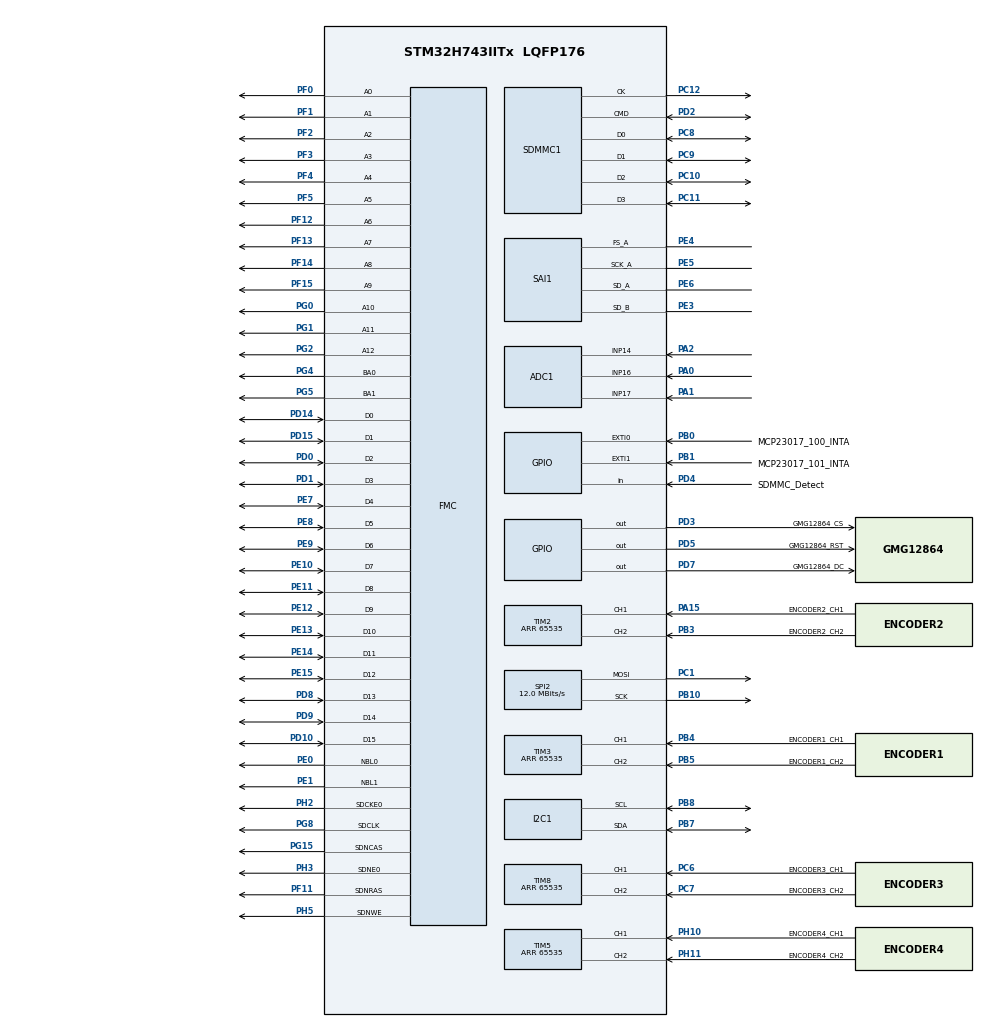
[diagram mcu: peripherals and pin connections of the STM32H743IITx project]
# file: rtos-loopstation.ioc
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ADC1.Channel-2\#ChannelRegularConversion=ADC_CHANNEL_16
ADC1.Channel-3\#ChannelRegularConversion=ADC_CHANNEL_17
ADC1.Channel-4\#ChannelRegularConversion=ADC_CHANNEL_14
ADC1.ContinuousConvMode=DISABLE
ADC1.EOCSelection=ADC_EOC_SINGLE_CONV
ADC1.LowPowerAutoWait=ENABLE
ADC1.NbrOfConversion=3
ADC1.NbrOfConversionFlag=1
ADC1.OffsetNumber-2\#ChannelRegularConversion=ADC_OFFSET_NONE
ADC1.OffsetNumber-3\#ChannelRegularConversion=ADC_OFFSET_NONE
ADC1.OffsetNumber-4\#ChannelRegularConversion=ADC_OFFSET_NONE
ADC1.OffsetSignedSaturation-2\#ChannelRegularConversion=DISABLE
ADC1.OffsetSignedSaturation-3\#ChannelRegularConversion=DISABLE
ADC1.OffsetSignedSaturation-4\#ChannelRegularConversion=DISABLE
ADC1.Overrun=ADC_OVR_DATA_PRESERVED
ADC1.Rank-2\#ChannelRegularConversion=1
ADC1.Rank-3\#ChannelRegularConversion=2
ADC1.Rank-4\#ChannelRegularConversion=3
ADC1.SamplingTime-2\#ChannelRegularConversion=ADC_SAMPLETIME_64CYCLES_5
ADC1.SamplingTime-3\#ChannelRegularConversion=ADC_SAMPLETIME_64CYCLES_5
ADC1.SamplingTime-4\#ChannelRegularConversion=ADC_SAMPLETIME_64CYCLES_5
ADC1.master=1
CORTEX_M7.AccessPermission_S-Cortex_Memory_Protection_Unit_Region1_Settings_S=MPU_REGION_FULL_ACCESS
CORTEX_M7.BaseAddress_S-Cortex_Memory_Protection_Unit_Region1_Settings_S=0xC0000000
CORTEX_M7.Enable_S-Cortex_Memory_Protection_Unit_Region1_Settings_S=MPU_REGION_ENABLE
CORTEX_M7.IsBufferable_S-Cortex_Memory_Protection_Unit_Region1_Settings_S=MPU_ACCESS_BUFFERABLE
CORTEX_M7.IsCacheable_S-Cortex_Memory_Protection_Unit_Region1_Settings_S=MPU_ACCESS_CACHEABLE
CORTEX_M7.IsShareable_S-Cortex_Memory_Protection_Unit_Region1_Settings_S=MPU_ACCESS_SHAREABLE
CORTEX_M7.Size_S-Cortex_Memory_Protection_Unit_Region1_Settings_S=MPU_REGION_SIZE_32MB
CORTEX_M7.default_mode_Activation=1
Dma.Request0=SPI2_TX
Dma.Request1=SAI1_A
Dma.Request2=SAI1_B
Dma.SAI1_A.1.Direction=DMA_MEMORY_TO_PERIPH
Dma.SAI1_A.1.EventEnable=DISABLE
Dma.SAI1_A.1.FIFOMode=DMA_FIFOMODE_DISABLE
Dma.SAI1_A.1.Instance=DMA1_Stream1
Dma.SAI1_A.1.MemDataAlignment=DMA_MDATAALIGN_WORD
Dma.SAI1_A.1.MemInc=DMA_MINC_ENABLE
Dma.SAI1_A.1.Mode=DMA_CIRCULAR
Dma.SAI1_A.1.PeriphDataAlignment=DMA_PDATAALIGN_WORD
Dma.SAI1_A.1.PeriphInc=DMA_PINC_DISABLE
Dma.SAI1_A.1.Polarity=HAL_DMAMUX_REQ_GEN_RISING
Dma.SAI1_A.1.Priority=DMA_PRIORITY_HIGH
Dma.SAI1_A.1.RequestNumber=1
Dma.SAI1_A.1.SignalID=NONE
Dma.SAI1_A.1.SyncEnable=DISABLE
Dma.SAI1_A.1.SyncPolarity=HAL_DMAMUX_SYNC_NO_EVENT
Dma.SAI1_A.1.SyncRequestNumber=1
Dma.SAI1_A.1.SyncSignalID=NONE
Dma.SAI1_B.2.Direction=DMA_PERIPH_TO_MEMORY
Dma.SAI1_B.2.EventEnable=DISABLE
Dma.SAI1_B.2.FIFOMode=DMA_FIFOMODE_DISABLE
Dma.SAI1_B.2.Instance=DMA1_Stream2
Dma.SAI1_B.2.MemDataAlignment=DMA_MDATAALIGN_WORD
Dma.SAI1_B.2.MemInc=DMA_MINC_ENABLE
Dma.SAI1_B.2.Mode=DMA_CIRCULAR
Dma.SAI1_B.2.PeriphDataAlignment=DMA_PDATAALIGN_WORD
Dma.SAI1_B.2.PeriphInc=DMA_PINC_DISABLE
Dma.SAI1_B.2.Polarity=HAL_DMAMUX_REQ_GEN_RISING
Dma.SAI1_B.2.Priority=DMA_PRIORITY_LOW
Dma.SAI1_B.2.RequestNumber=1
Dma.SAI1_B.2.SignalID=NONE
Dma.SAI1_B.2.SyncEnable=DISABLE
Dma.SAI1_B.2.SyncPolarity=HAL_DMAMUX_SYNC_NO_EVENT
Dma.SAI1_B.2.SyncRequestNumber=1
Dma.SAI1_B.2.SyncSignalID=NONE
Dma.SPI2_TX.0.Direction=DMA_MEMORY_TO_PERIPH
Dma.SPI2_TX.0.EventEnable=DISABLE
Dma.SPI2_TX.0.FIFOMode=DMA_FIFOMODE_DISABLE
Dma.SPI2_TX.0.Instance=DMA1_Stream0
Dma.SPI2_TX.0.MemDataAlignment=DMA_MDATAALIGN_BYTE
Dma.SPI2_TX.0.MemInc=DMA_MINC_ENABLE
Dma.SPI2_TX.0.Mode=DMA_NORMAL
Dma.SPI2_TX.0.PeriphDataAlignment=DMA_PDATAALIGN_BYTE
Dma.SPI2_TX.0.PeriphInc=DMA_PINC_DISABLE
Dma.SPI2_TX.0.Polarity=HAL_DMAMUX_REQ_GEN_RISING
Dma.SPI2_TX.0.Priority=DMA_PRIORITY_LOW
Dma.SPI2_TX.0.RequestNumber=1
Dma.SPI2_TX.0.SignalID=NONE
Dma.SPI2_TX.0.SyncEnable=DISABLE
Dma.SPI2_TX.0.SyncPolarity=HAL_DMAMUX_SYNC_NO_EVENT
Dma.SPI2_TX.0.SyncRequestNumber=1
Dma.SPI2_TX.0.SyncSignalID=NONE
FATFS.BSP.number=1
FATFS0.BSP.STBoard=false
FATFS0.BSP.api=Unknown
FATFS0.BSP.instance=PD4
FATFS0.BSP.ip=GPIO
FATFS0.BSP.mode=Input
FATFS0.BSP.name=Detect_SDIO
FATFS0.BSP.solution=PD4
FMC.CASLatency1=FMC_SDRAM_CAS_LATENCY_2
FMC.ColumnBitsNumber1=FMC_SDRAM_COLUMN_BITS_NUM_9
FMC.ReadBurst1=FMC_SDRAM_RBURST_ENABLE
FMC.ReadBurst2=FMC_SDRAM_RBURST_ENABLE
FMC.ReadPipeDelay1=FMC_SDRAM_RPIPE_DELAY_0
FMC.SDClockPeriod1=FMC_SDRAM_CLOCK_PERIOD_3
FMC.SDClockPeriod2=FMC_SDRAM_CLOCK_PERIOD_3
FMC.WriteProtection1=FMC_SDRAM_WRITE_PROTECTION_DISABLE
FREERTOS.Events01=system_init_event,Dynamic,NULL
FREERTOS.Mutexes01=i2c1_mutex,Dynamic,NULL,Available;system_parameter_mutex,Dynamic,NULL,Available;fx_parameter_mutex,Dynamic,NULL,Available
FREERTOS.Queues01=input_event_queue,16,RtosMessage_InputEvent,0,Dynamic,NULL,NULL;display_snapshot_mailbox,1,RtosMessage_DisplaySnapshot,0,Dynamic,NULL,NULL;state_event_queue,16,RtosMessage_StateEvent,0,Dynamic,NULL,NULL;audio_event_snapshot_mailbox,1,RtosMessage_AudioEventSnapshot,0,Dynamic,NULL,NULL;audio_dma_event,16,RtosMessage_AudioDmaEvent,0,Dynamic,NULL,NULL
FREERTOS.Tasks01=defaultTask,8,128,StartDefaultTask,Default,NULL,Dynamic,NULL,NULL;inputTask,32,128,InputTask_Init,As external,&input_init_params,Dynamic,NULL,NULL;displayTask,16,512,DisplayTask_Init,As external,&display_init_params,Dynamic,NULL,NULL;stateTask,24,1024,StateTask_Init,As external,&state_init_params,Dynamic,NULL,NULL;adcInputTask,32,128,AdcInputTask_Init,As external,&adc_input_init_params,Dynamic,NULL,NULL;systemTask,55,1024,SystemTask_Init,As external,&system_init_params,Dynamic,NULL,NULL;audioTask,40,128,AudioTask_Init,As external,&audio_init_params,Dynamic,NULL,NULL
FREERTOS.configENABLE_FPU=1
FREERTOS.configRECORD_STACK_HIGH_ADDRESS=1
I2C1.Timing=0x307075B1
Mcu.Family=STM32H7
Mcu.Name=STM32H743IITx
Mcu.Package=LQFP176
Mdma.MDMA_Channel0.Request0=SW
Mdma.MDMA_Channel0.RequestsNb=1
Mdma.MDMA_Channel0.SW.0.BlockCount=0
Mdma.MDMA_Channel0.SW.0.BlockDataLength=0
Mdma.MDMA_Channel0.SW.0.BufferTransferLength=128
Mdma.MDMA_Channel0.SW.0.CircularMode=MDMA_LINEAR_LIST
Mdma.MDMA_Channel0.SW.0.DataAlignment=MDMA_DATAALIGN_PACKENABLE
Mdma.MDMA_Channel0.SW.0.DestBlockAddressOffset=0
Mdma.MDMA_Channel0.SW.0.DestBurst=MDMA_DEST_BURST_SINGLE
Mdma.MDMA_Channel0.SW.0.DestDataSize=MDMA_DEST_DATASIZE_WORD
Mdma.MDMA_Channel0.SW.0.DestinationInc=MDMA_DEST_INC_WORD
Mdma.MDMA_Channel0.SW.0.DstAddress=0
Mdma.MDMA_Channel0.SW.0.Endianness=MDMA_LITTLE_ENDIANNESS_PRESERVE
Mdma.MDMA_Channel0.SW.0.Instance=MDMA_Channel0
Mdma.MDMA_Channel0.SW.0.MaskAddress=0
Mdma.MDMA_Channel0.SW.0.MaskData=0
Mdma.MDMA_Channel0.SW.0.Priority=MDMA_PRIORITY_MEDIUM
Mdma.MDMA_Channel0.SW.0.Rank=First
Mdma.MDMA_Channel0.SW.0.SourceBlockAddressOffset=0
Mdma.MDMA_Channel0.SW.0.SourceBurst=MDMA_SOURCE_BURST_SINGLE
Mdma.MDMA_Channel0.SW.0.SourceDataSize=MDMA_SRC_DATASIZE_WORD
Mdma.MDMA_Channel0.SW.0.SourceInc=MDMA_SRC_INC_WORD
Mdma.MDMA_Channel0.SW.0.SrcAddress=0
Mdma.MDMA_Channel0.SW.0.TransferTriggerMode=MDMA_BLOCK_TRANSFER
Mdma.RequestSet0=MDMA_Channel0
Mdma.RequestSetsNb=1
NVIC.DMA1_Stream0_IRQn=true\:5\:0\:false\:false\:true\:true\:false\:true\:true
NVIC.DMA1_Stream1_IRQn=true\:5\:0\:false\:false\:true\:true\:false\:true\:true
NVIC.DMA1_Stream2_IRQn=true\:5\:0\:false\:false\:true\:true\:false\:true\:true
NVIC.EXTI0_IRQn=true\:5\:0\:false\:false\:true\:true\:true\:true\:true
NVIC.EXTI1_IRQn=true\:5\:0\:false\:false\:true\:true\:true\:true\:true
NVIC.MDMA_IRQn=true\:5\:0\:false\:false\:true\:false\:false\:true\:true
NVIC.PriorityGroup=NVIC_PRIORITYGROUP_4
NVIC.SPI2_IRQn=true\:5\:0\:false\:false\:true\:true\:false\:true\:true
NVIC.TIM2_IRQn=true\:5\:0\:false\:false\:true\:true\:true\:true\:true
NVIC.TIM3_IRQn=true\:5\:0\:false\:false\:true\:true\:true\:true\:true
NVIC.TIM5_IRQn=true\:5\:0\:false\:false\:true\:true\:true\:true\:true
NVIC.TIM7_IRQn=true\:15\:0\:false\:false\:true\:false\:false\:true\:true
NVIC.TIM8_CC_IRQn=true\:5\:0\:false\:false\:true\:true\:true\:true\:true
NVIC.TimeBase=TIM7_IRQn
NVIC.TimeBaseIP=TIM7
PA0.Mode=IN16-Single-Ended
PA0.Signal=ADC1_INP16
PA1.Mode=IN17-Single-Ended
PA1.Signal=ADC1_INP17
PA13\ (JTMS/SWDIO).Mode=Serial_Wire
PA13\ (JTMS/SWDIO).Signal=DEBUG_JTMS-SWDIO
PA14\ (JTCK/SWCLK).Mode=Serial_Wire
PA14\ (JTCK/SWCLK).Signal=DEBUG_JTCK-SWCLK
PA15\ (JTDI).GPIO_Label=ENCODER2_CH1
PA15\ (JTDI).GPIO_PuPd=GPIO_PULLUP
PA15\ (JTDI).Signal=S_TIM2_CH1_ETR
PA2.Signal=ADCx_INP14
PB0.GPIO_Label=MCP23017_100_INTA
PB0.Signal=GPXTI0
PB1.GPIO_Label=MCP23017_101_INTA
PB1.Signal=GPXTI1
PB10.Mode=TX_Only_Simplex_Unidirect_Master
PB10.Signal=SPI2_SCK
PB3\ (JTDO/TRACESWO).GPIO_Label=ENCODER2_CH2
PB3\ (JTDO/TRACESWO).GPIO_PuPd=GPIO_PULLUP
PB3\ (JTDO/TRACESWO).Signal=S_TIM2_CH2
PB4\ (NJTRST).GPIO_Label=ENCODER1_CH1
PB4\ (NJTRST).GPIO_PuPd=GPIO_PULLUP
PB4\ (NJTRST).Signal=S_TIM3_CH1
PB5.GPIO_Label=ENCODER1_CH2
PB5.GPIO_PuPd=GPIO_PULLUP
PB5.Signal=S_TIM3_CH2
PB7.Mode=I2C
PB7.Signal=I2C1_SDA
PB8.Mode=I2C
PB8.Signal=I2C1_SCL
PC1.Mode=TX_Only_Simplex_Unidirect_Master
PC1.Signal=SPI2_MOSI
PC10.Mode=SD_4_bits_Wide_bus
PC10.Signal=SDMMC1_D2
PC11.Mode=SD_4_bits_Wide_bus
PC11.Signal=SDMMC1_D3
PC12.GPIO_PuPd=GPIO_NOPULL
PC12.Mode=SD_4_bits_Wide_bus
PC12.Signal=SDMMC1_CK
PC6.GPIO_Label=ENCODER3_CH1
PC6.GPIO_PuPd=GPIO_PULLUP
PC6.Signal=S_TIM8_CH1
PC7.GPIO_Label=ENCODER3_CH2
PC7.GPIO_PuPd=GPIO_PULLUP
PC7.Signal=S_TIM8_CH2
PC8.GPIO_PuPd=GPIO_PULLUP
PC8.Mode=SD_4_bits_Wide_bus
PC8.Signal=SDMMC1_D0
PC9.Mode=SD_4_bits_Wide_bus
PC9.Signal=SDMMC1_D1
PD0.Signal=FMC_D2_DA2
PD1.Signal=FMC_D3_DA3
PD10.Signal=FMC_D15_DA15
PD14.Signal=FMC_D0_DA0
PD15.Signal=FMC_D1_DA1
PD2.GPIO_PuPd=GPIO_PULLUP
PD2.Mode=SD_4_bits_Wide_bus
PD2.Signal=SDMMC1_CMD
PD3.GPIO_Label=GMG12864_CS
PD3.Signal=GPIO_Output
PD4.GPIO_Label=SDMMC_Detect
PD4.GPIO_PuPd=GPIO_PULLUP
PD4.Signal=GPIO_Input
PD5.GPIO_Label=GMG12864_RST
PD5.Signal=GPIO_Output
PD7.GPIO_Label=GMG12864_DC
PD7.Signal=GPIO_Output
PD8.Signal=FMC_D13_DA13
PD9.Signal=FMC_D14_DA14
PE0.Signal=FMC_NBL0
PE1.Signal=FMC_NBL1
PE10.Signal=FMC_D7_DA7
PE11.Signal=FMC_D8_DA8
PE12.Signal=FMC_D9_DA9
PE13.Signal=FMC_D10_DA10
PE14.Signal=FMC_D11_DA11
PE15.Signal=FMC_D12_DA12
PE3.Mode=SAI_B_SyncSlave
PE3.PinAttribute=Free
PE3.Signal=SAI1_SD_B
PE4.Mode=SAI_A_Master
PE4.PinAttribute=Free
PE4.Signal=SAI1_FS_A
PE5.Mode=SAI_A_Master
PE5.PinAttribute=Free
PE5.Signal=SAI1_SCK_A
PE6.Mode=SAI_A_Master
PE6.PinAttribute=Free
PE6.Signal=SAI1_SD_A
PE7.Signal=FMC_D4_DA4
PE8.Signal=FMC_D5_DA5
PE9.Signal=FMC_D6_DA6
PF0.PinAttribute=Free
PF0.Signal=FMC_A0
PF1.Signal=FMC_A1
PF11.Signal=FMC_SDNRAS
PF12.Signal=FMC_A6
PF13.Signal=FMC_A7
PF14.Signal=FMC_A8
PF15.Signal=FMC_A9
PF2.Signal=FMC_A2
PF3.Signal=FMC_A3
PF4.Signal=FMC_A4
PF5.Signal=FMC_A5
PG0.Signal=FMC_A10
PG1.Signal=FMC_A11
PG15.Signal=FMC_SDNCAS
PG2.Signal=FMC_A12
PG4.Signal=FMC_A14_BA0
PG5.Signal=FMC_A15_BA1
PG8.Signal=FMC_SDCLK
PH10.GPIO_Label=ENCODER4_CH1
PH10.GPIO_PuPd=GPIO_PULLUP
PH10.Signal=S_TIM5_CH1
PH11.GPIO_Label=ENCODER4_CH2
PH11.GPIO_PuPd=GPIO_PULLUP
PH11.Signal=S_TIM5_CH2
PH2.Mode=SdramChipSelect1_1
PH2.Signal=FMC_SDCKE0
PH3.Mode=SdramChipSelect1_1
PH3.Signal=FMC_SDNE0
PH5.Signal=FMC_SDNWE
ProjectManager.HeapSize=0x200
ProjectManager.StackSize=0x400
ProjectManager.TargetToolchain=CMake
RCC.ADCFreq_Value=80000000
RCC.APB1Freq_Value=120000000
RCC.APB2Freq_Value=120000000
RCC.APB3Freq_Value=120000000
RCC.APB4Freq_Value=120000000
RCC.CortexFreq_Value=480000000
RCC.D1PPRE=RCC_APB3_DIV2
RCC.D2PPRE1=RCC_APB1_DIV2
RCC.D2PPRE2=RCC_APB2_DIV2
RCC.D3PPRE=RCC_APB4_DIV2
RCC.DIVM1=4
RCC.DIVM2=4
RCC.DIVM3=25
RCC.DIVN1=60
RCC.DIVN2=10
RCC.DIVN3=176
RCC.DIVP3=40
RCC.DIVQ1=5
RCC.DIVR1=42
RCC.HCLKFreq_Value=240000000
RCC.HPRE=RCC_HCLK_DIV2
RCC.PLL2FRACN=0
RCC.PLL3FRACN=3277
RCC.PLLFRACN=0
RCC.SAI1CLockSelection=RCC_SAI1CLKSOURCE_PLL3
RCC.SYSCLKFreq_VALUE=480000000
RCC.SYSCLKSource=RCC_SYSCLKSOURCE_PLLCLK
RCC.USBFreq_Value=192000000
SAI1.AudioFrequency-SAI_A_Master=SAI_AUDIO_FREQUENCY_44K
SAI1.BasicDataSize-SAI_A_Master=SAI_PROTOCOL_DATASIZE_32BIT
SAI1.BasicDataSize-SAI_B_SyncSlave=SAI_PROTOCOL_DATASIZE_32BIT
SAI1.ErrorAudioFreq-SAI_A_Master=0.0 %
SAI1.InitProtocol-SAI_A_Master=Enable
SAI1.InitProtocol-SAI_B_SyncSlave=Enable
SAI1.Instance-SAI_A_Master=SAI$Index_Block_A
SAI1.Instance-SAI_B_SyncSlave=SAI$Index_Block_B
SAI1.MClockEnable=SAI_MASTERCLOCK_DISABLE
SAI1.MClockEnable-SAI_A_Master=SAI_MASTERCLOCK_DISABLE
SAI1.RealAudioFreq-SAI_A_Master=44.1 KHz
SAI1.VirtualMode-SAI_A_Master=VM_MASTER
SAI1.VirtualMode-SAI_B_SyncSlave=VM_SLAVE
SAI1.VirtualProtocol-SAI_A_BASIC=VM_BASIC_PROTOCOL
SAI1.VirtualProtocol-SAI_B_BASIC=VM_BASIC_PROTOCOL
SDMMC1.ClockDiv=24
SH.ADCx_INP14.0=ADC1_INP14,IN14-Single-Ended
SH.FMC_A0.0=FMC_A0,13b-sda1
SH.FMC_A1.0=FMC_A1,13b-sda1
SH.FMC_A10.0=FMC_A10,13b-sda1
SH.FMC_A11.0=FMC_A11,13b-sda1
SH.FMC_A12.0=FMC_A12,13b-sda1
SH.FMC_A14_BA0.0=FMC_BA0,FourSdramBanks1
SH.FMC_A15_BA1.0=FMC_BA1,FourSdramBanks1
SH.FMC_A2.0=FMC_A2,13b-sda1
SH.FMC_A3.0=FMC_A3,13b-sda1
SH.FMC_A4.0=FMC_A4,13b-sda1
SH.FMC_A5.0=FMC_A5,13b-sda1
SH.FMC_A6.0=FMC_A6,13b-sda1
SH.FMC_A7.0=FMC_A7,13b-sda1
SH.FMC_A8.0=FMC_A8,13b-sda1
SH.FMC_A9.0=FMC_A9,13b-sda1
SH.FMC_D0_DA0.0=FMC_D0,sd-16b-d1
SH.FMC_D10_DA10.0=FMC_D10,sd-16b-d1
SH.FMC_D11_DA11.0=FMC_D11,sd-16b-d1
SH.FMC_D12_DA12.0=FMC_D12,sd-16b-d1
SH.FMC_D13_DA13.0=FMC_D13,sd-16b-d1
SH.FMC_D14_DA14.0=FMC_D14,sd-16b-d1
SH.FMC_D15_DA15.0=FMC_D15,sd-16b-d1
SH.FMC_D1_DA1.0=FMC_D1,sd-16b-d1
SH.FMC_D2_DA2.0=FMC_D2,sd-16b-d1
SH.FMC_D3_DA3.0=FMC_D3,sd-16b-d1
SH.FMC_D4_DA4.0=FMC_D4,sd-16b-d1
SH.FMC_D5_DA5.0=FMC_D5,sd-16b-d1
SH.FMC_D6_DA6.0=FMC_D6,sd-16b-d1
SH.FMC_D7_DA7.0=FMC_D7,sd-16b-d1
SH.FMC_D8_DA8.0=FMC_D8,sd-16b-d1
SH.FMC_D9_DA9.0=FMC_D9,sd-16b-d1
SH.FMC_NBL0.0=FMC_NBL0,Sd2ByteEnable1
SH.FMC_NBL1.0=FMC_NBL1,Sd2ByteEnable1
SH.FMC_SDCLK.0=FMC_SDCLK,13b-sda1
SH.FMC_SDNCAS.0=FMC_SDNCAS,13b-sda1
SH.FMC_SDNRAS.0=FMC_SDNRAS,13b-sda1
SH.FMC_SDNWE.0=FMC_SDNWE,13b-sda1
SH.S_TIM2_CH1_ETR.0=TIM2_CH1,Encoder_Interface
SH.S_TIM2_CH2.0=TIM2_CH2,Encoder_Interface
SH.S_TIM3_CH1.0=TIM3_CH1,Encoder_Interface
SH.S_TIM3_CH2.0=TIM3_CH2,Encoder_Interface
SH.S_TIM5_CH1.0=TIM5_CH1,Encoder_Interface
SH.S_TIM5_CH2.0=TIM5_CH2,Encoder_Interface
SH.S_TIM8_CH1.0=TIM8_CH1,Encoder_Interface
SH.S_TIM8_CH2.0=TIM8_CH2,Encoder_Interface
SPI2.BaudRatePrescaler=SPI_BAUDRATEPRESCALER_16
SPI2.CalculateBaudRate=12.0 MBits/s
SPI2.DataSize=SPI_DATASIZE_8BIT
SPI2.Direction=SPI_DIRECTION_2LINES_TXONLY
SPI2.Mode=SPI_MODE_MASTER
SPI2.VirtualType=VM_MASTER
TIM2.EncoderMode=TIM_ENCODERMODE_TI1
TIM2.IC1Filter=0
TIM2.IC2Filter=0
TIM2.Period=65535
TIM3.EncoderMode=TIM_ENCODERMODE_TI1
TIM3.IC1Filter=0
TIM3.IC2Filter=0
TIM3.Period=65535
TIM5.EncoderMode=TIM_ENCODERMODE_TI1
TIM5.IC1Filter=0
TIM5.IC2Filter=0
TIM5.Period=65535
TIM8.EncoderMode=TIM_ENCODERMODE_TI1
TIM8.IC1Filter=0
TIM8.IC2Filter=0
TIM8.Period=65535
VP_FATFS_VS_SDIO.Mode=SDIO
VP_FREERTOS_VS_CMSIS_V2.Mode=CMSIS_V2
VP_MEMORYMAP_VS_MEMORYMAP.Mode=CurAppReg
VP_SAI1_VP_$IpInstance_SAIA_SAI_BASIC.Mode=SAI_A_BASIC
VP_SAI1_VP_$IpInstance_SAIB_SAI_BASIC.Mode=SAI_B_BASIC
VP_SYS_VS_tim7.Mode=TIM7
board=custom

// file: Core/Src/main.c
/* USER CODE BEGIN Header */
/**
 ******************************************************************************
 * @file           : main.c
 * @brief          : Main program body
 ******************************************************************************
 * @attention
 *
 * Copyright (c) 2026 STMicroelectronics.
 * All rights reserved.
 *
 * This software is licensed under terms that can be found in the LICENSE file
 * in the root directory of this software component.
 * If no LICENSE file comes with this software, it is provided AS-IS.
 *
 ******************************************************************************
 */
/* USER CODE END Header */
#include "main.h"
#include "FreeRTOS.h"
#include "cmsis_os2.h"
#include "fatfs.h"

/* USER CODE BEGIN Includes */
#ifdef LOOPSTATION_SYSTEMVIEW
#include "SEGGER_SYSVIEW.h"
#endif
#include "app_messages.h"
#include "debug_fault.h"
#include "display_initparams.h"
#include "input_initparams.h"
#include "input_event_sender.h"
#include "adc_input_initparams.h"
#include "state_initparams.h"
#include "system_initparams.h"
#include "audio_initparams.h"
#include "audio_event_sender.h"
/* USER CODE END Includes */

ADC_HandleTypeDef hadc1;

I2C_HandleTypeDef hi2c1;

SAI_HandleTypeDef hsai_BlockA1;
SAI_HandleTypeDef hsai_BlockB1;
DMA_HandleTypeDef hdma_sai1_a;
DMA_HandleTypeDef hdma_sai1_b;

SD_HandleTypeDef hsd1;

SPI_HandleTypeDef hspi2;
DMA_HandleTypeDef hdma_spi2_tx;

TIM_HandleTypeDef htim2;
TIM_HandleTypeDef htim3;
TIM_HandleTypeDef htim5;
TIM_HandleTypeDef htim8;

MDMA_HandleTypeDef hmdma_mdma_channel0_sw_0;
SDRAM_HandleTypeDef hsdram1;

/* Definitions for defaultTask */
osThreadId_t defaultTaskHandle;
const osThreadAttr_t defaultTask_attributes = {
  .name = "defaultTask",
  .stack_size = 128 * 4,
  .priority = (osPriority_t) osPriorityLow,
};
/* Definitions for inputTask */
osThreadId_t inputTaskHandle;
const osThreadAttr_t inputTask_attributes = {
  .name = "inputTask",
  .stack_size = 128 * 4,
  .priority = (osPriority_t) osPriorityAboveNormal,
};
/* Definitions for displayTask */
osThreadId_t displayTaskHandle;
const osThreadAttr_t displayTask_attributes = {
  .name = "displayTask",
  .stack_size = 512 * 4,
  .priority = (osPriority_t) osPriorityBelowNormal,
};
/* Definitions for stateTask */
osThreadId_t stateTaskHandle;
const osThreadAttr_t stateTask_attributes = {
  .name = "stateTask",
  .stack_size = 1024 * 4,
  .priority = (osPriority_t) osPriorityNormal,
};
/* Definitions for adcInputTask */
osThreadId_t adcInputTaskHandle;
const osThreadAttr_t adcInputTask_attributes = {
  .name = "adcInputTask",
  .stack_size = 128 * 4,
  .priority = (osPriority_t) osPriorityAboveNormal,
};
/* Definitions for systemTask */
osThreadId_t systemTaskHandle;
const osThreadAttr_t systemTask_attributes = {
  .name = "systemTask",
  .stack_size = 1024 * 4,
  .priority = (osPriority_t) osPriorityRealtime7,
};
/* Definitions for audioTask */
osThreadId_t audioTaskHandle;
const osThreadAttr_t audioTask_attributes = {
  .name = "audioTask",
  .stack_size = 128 * 4,
  .priority = (osPriority_t) osPriorityHigh,
};
/* Definitions for input_event_queue */
osMessageQueueId_t input_event_queueHandle;
const osMessageQueueAttr_t input_event_queue_attributes = {
  .name = "input_event_queue"
};
/* Definitions for display_snapshot_mailbox */
osMessageQueueId_t display_snapshot_mailboxHandle;
const osMessageQueueAttr_t display_snapshot_mailbox_attributes = {
  .name = "display_snapshot_mailbox"
};
/* Definitions for state_event_queue */
osMessageQueueId_t state_event_queueHandle;
const osMessageQueueAttr_t state_event_queue_attributes = {
  .name = "state_event_queue"
};
/* Definitions for audio_event_snapshot_mailbox */
osMessageQueueId_t audio_event_snapshot_mailboxHandle;
const osMessageQueueAttr_t audio_event_snapshot_mailbox_attributes = {
  .name = "audio_event_snapshot_mailbox"
};
/* Definitions for audio_dma_event */
osMessageQueueId_t audio_dma_eventHandle;
const osMessageQueueAttr_t audio_dma_event_attributes = {
  .name = "audio_dma_event"
};
/* Definitions for i2c1_mutex */
osMutexId_t i2c1_mutexHandle;
const osMutexAttr_t i2c1_mutex_attributes = {
  .name = "i2c1_mutex"
};
/* Definitions for system_parameter_mutex */
osMutexId_t system_parameter_mutexHandle;
const osMutexAttr_t system_parameter_mutex_attributes = {
  .name = "system_parameter_mutex"
};
/* Definitions for fx_parameter_mutex */
osMutexId_t fx_parameter_mutexHandle;
const osMutexAttr_t fx_parameter_mutex_attributes = {
  .name = "fx_parameter_mutex"
};
/* Definitions for system_init_event */
osEventFlagsId_t system_init_eventHandle;
const osEventFlagsAttr_t system_init_event_attributes = {
  .name = "system_init_event"
};
/* USER CODE BEGIN PV */
static InputInitParams input_init_params;
static DisplayInitParams display_init_params;
static StateInitParams state_init_params;
static AdcInputInitParams adc_input_init_params;
static SystemInitParams system_init_params;
static AudioInitParams audio_init_params;

/* USER CODE END PV */

void SystemClock_Config(void);
void PeriphCommonClock_Config(void);
static void MPU_Config(void);
static void MX_GPIO_Init(void);
static void MX_DMA_Init(void);
static void MX_MDMA_Init(void);
static void MX_SDMMC1_SD_Init(void);
static void MX_SPI2_Init(void);
static void MX_I2C1_Init(void);
static void MX_TIM3_Init(void);
static void MX_ADC1_Init(void);
static void MX_SAI1_Init(void);
static void MX_TIM2_Init(void);
static void MX_FMC_Init(void);
static void MX_TIM5_Init(void);
static void MX_TIM8_Init(void);
void StartDefaultTask(void *argument);
extern void InputTask_Init(void *argument);
extern void DisplayTask_Init(void *argument);
extern void StateTask_Init(void *argument);
extern void AdcInputTask_Init(void *argument);
extern void SystemTask_Init(void *argument);
extern void AudioTask_Init(void *argument);

/* USER CODE BEGIN PFP */
// 이 함수는 전역 콜백 함수이므로 애플리케이션에 처리를 위임한다.
void HAL_GPIO_EXTI_Callback(uint16_t GPIO_Pin)
{
    InputEvent_SendMcp23017(input_event_queueHandle, GPIO_Pin);
}

void HAL_TIM_IC_CaptureCallback(TIM_HandleTypeDef *htim)
{
    if (htim->Instance == TIM2) {
        InputEvent_SendEncoderA(input_event_queueHandle,
                               __HAL_TIM_IS_TIM_COUNTING_DOWN(htim));
    }

    if (htim->Instance == TIM3) {
        InputEvent_SendEncoderB(input_event_queueHandle,
                               __HAL_TIM_IS_TIM_COUNTING_DOWN(htim));
    }

    if (htim->Instance == TIM5) {
        InputEvent_SendEncoderC(input_event_queueHandle,
                               __HAL_TIM_IS_TIM_COUNTING_DOWN(htim));
    }

    if (htim->Instance == TIM8) {
        InputEvent_SendEncoderD(input_event_queueHandle,
                               __HAL_TIM_IS_TIM_COUNTING_DOWN(htim));
    }
}

void HAL_SAI_RxHalfCpltCallback(SAI_HandleTypeDef* hsai) {
    if (hsai == &hsai_BlockB1) {
        AudioDmaEvent_SendSaiRxHalfCplt(audio_dma_eventHandle);
    }
}

void HAL_SAI_RxCpltCallback(SAI_HandleTypeDef *hsai) {
    if (hsai == &hsai_BlockB1) {
        AudioDmaEvent_SendSaiRxCplt(audio_dma_eventHandle);
    }
}

void HAL_SAI_TxHalfCpltCallback(SAI_HandleTypeDef *hsai) {
    if (hsai == &hsai_BlockA1) {
        AudioDmaEvent_SendSaiTxHalfCplt(audio_dma_eventHandle);
    }
}

void HAL_SAI_TxCpltCallback(SAI_HandleTypeDef *hsai) {
    if (hsai == &hsai_BlockA1) {
        AudioDmaEvent_SendSaiTxCplt(audio_dma_eventHandle);
    }
}

void HAL_SAI_ErrorCallback(SAI_HandleTypeDef *hsai) {
    if (hsai == &hsai_BlockA1 || hsai == &hsai_BlockB1) {
        AudioDmaEvent_SendSaiError(audio_dma_eventHandle);
    }
}
/* USER CODE END PFP */

int main(void)
{

  /* MPU Configuration--------------------------------------------------------*/
  MPU_Config();

  /* MCU Configuration--------------------------------------------------------*/

  /* Reset of all peripherals, Initializes the Flash interface and the Systick. */
  HAL_Init();

  /* Configure the system clock */
  SystemClock_Config();

  /* Configure the peripherals common clocks */
  PeriphCommonClock_Config();

  /* USER CODE BEGIN SysInit */
#ifdef LOOPSTATION_SYSTEMVIEW
  SEGGER_SYSVIEW_Conf();
#endif

  /* USER CODE END SysInit */

  /* Initialize all configured peripherals */
  MX_GPIO_Init();
  MX_DMA_Init();
  MX_MDMA_Init();
  MX_SDMMC1_SD_Init();
  MX_FATFS_Init();
  MX_SPI2_Init();
  MX_I2C1_Init();
  MX_TIM3_Init();
  MX_ADC1_Init();
  MX_SAI1_Init();
  MX_TIM2_Init();
  MX_FMC_Init();
  MX_TIM5_Init();
  MX_TIM8_Init();
  /* USER CODE BEGIN 2 */
  HAL_TIM_Encoder_Start_IT(&htim2, htim2.Channel);
  HAL_TIM_Encoder_Start_IT(&htim3, htim3.Channel);
  HAL_TIM_Encoder_Start_IT(&htim5, htim5.Channel);
  HAL_TIM_Encoder_Start_IT(&htim8, htim8.Channel);
  /* USER CODE END 2 */

  /* Init scheduler */
  osKernelInitialize();
  /* Create the mutex(es) */
  /* creation of i2c1_mutex */
  i2c1_mutexHandle = osMutexNew(&i2c1_mutex_attributes);

  /* creation of system_parameter_mutex */
  system_parameter_mutexHandle = osMutexNew(&system_parameter_mutex_attributes);

  /* creation of fx_parameter_mutex */
  fx_parameter_mutexHandle = osMutexNew(&fx_parameter_mutex_attributes);

  /* Create the queue(s) */
  /* creation of input_event_queue */
  input_event_queueHandle = osMessageQueueNew (16, sizeof(RtosMessage_InputEvent), &input_event_queue_attributes);

  /* creation of display_snapshot_mailbox */
  display_snapshot_mailboxHandle = osMessageQueueNew (1, sizeof(RtosMessage_DisplaySnapshot), &display_snapshot_mailbox_attributes);

  /* creation of state_event_queue */
  state_event_queueHandle = osMessageQueueNew (16, sizeof(RtosMessage_StateEvent), &state_event_queue_attributes);

  /* creation of audio_event_snapshot_mailbox */
  audio_event_snapshot_mailboxHandle = osMessageQueueNew (1, sizeof(RtosMessage_AudioEventSnapshot), &audio_event_snapshot_mailbox_attributes);

  /* creation of audio_dma_event */
  audio_dma_eventHandle = osMessageQueueNew (16, sizeof(RtosMessage_AudioDmaEvent), &audio_dma_event_attributes);

  /* USER CODE BEGIN RTOS_QUEUES */
  input_init_params.input_event_queue = input_event_queueHandle;
  input_init_params.state_event_queue = state_event_queueHandle;
  input_init_params.hi2c = &hi2c1;
  input_init_params.i2c1_mutex = i2c1_mutexHandle;

  adc_input_init_params.hadc = &hadc1;
  adc_input_init_params.input_message_queue = input_event_queueHandle;

  display_init_params.display_snapshot_mailbox = display_snapshot_mailboxHandle;
  display_init_params.hspi = &hspi2;
  display_init_params.hi2c = &hi2c1;
  display_init_params.i2c1_mutex = i2c1_mutexHandle;
  display_init_params.CS_Port = GMG12864_CS_GPIO_Port;
  display_init_params.CS_Pin = GMG12864_CS_Pin;
  display_init_params.RST_Port = GMG12864_RST_GPIO_Port;
  display_init_params.RST_Pin = GMG12864_RST_Pin;
  display_init_params.DC_Port = GMG12864_DC_GPIO_Port;
  display_init_params.DC_Pin = GMG12864_DC_Pin;

  state_init_params.state_event_queue = state_event_queueHandle;
  state_init_params.display_snapshot_mailbox = display_snapshot_mailboxHandle;
  state_init_params.audio_event_snapshot_mailbox = audio_event_snapshot_mailboxHandle;
  state_init_params.hi2c = &hi2c1;
  state_init_params.i2c_mutex = i2c1_mutexHandle;

  system_init_params.store_init_params.system_parameter_mutex = system_parameter_mutexHandle;
  system_init_params.store_init_params.fx_parameter_mutex = fx_parameter_mutexHandle;
  system_init_params.gmg12864_init_params.hspi = &hspi2;
  system_init_params.gmg12864_init_params.CS_Port = GMG12864_CS_GPIO_Port;
  system_init_params.gmg12864_init_params.CS_Pin = GMG12864_CS_Pin;
  system_init_params.gmg12864_init_params.RST_Port = GMG12864_RST_GPIO_Port;
  system_init_params.gmg12864_init_params.RST_Pin = GMG12864_RST_Pin;
  system_init_params.gmg12864_init_params.DC_Port = GMG12864_DC_GPIO_Port;
  system_init_params.gmg12864_init_params.DC_Pin = GMG12864_DC_Pin;
  system_init_params.mcp23017_init_params.hi2c = &hi2c1;
  system_init_params.mcp23017_init_params.i2c1_mutex = i2c1_mutexHandle;
  system_init_params.sdram_init_params.hsdram = &hsdram1;

  audio_init_params.hsai_tx = &hsai_BlockA1;
  audio_init_params.hsai_rx = &hsai_BlockB1;
  audio_init_params.hsdram = &hsdram1;
  audio_init_params.system_init_event = system_init_eventHandle;
  audio_init_params.audio_event_snapshot_mailbox = audio_event_snapshot_mailboxHandle;
  audio_init_params.audio_dma_event_queue = audio_dma_eventHandle;
  /* USER CODE END RTOS_QUEUES */

  /* Create the thread(s) */
  /* creation of defaultTask */
  defaultTaskHandle = osThreadNew(StartDefaultTask, NULL, &defaultTask_attributes);

  /* creation of inputTask */
  inputTaskHandle = osThreadNew(InputTask_Init, (void*) &input_init_params, &inputTask_attributes);

  /* creation of displayTask */
  displayTaskHandle = osThreadNew(DisplayTask_Init, (void*) &display_init_params, &displayTask_attributes);

  /* creation of stateTask */
  stateTaskHandle = osThreadNew(StateTask_Init, (void*) &state_init_params, &stateTask_attributes);

  /* creation of adcInputTask */
  adcInputTaskHandle = osThreadNew(AdcInputTask_Init, (void*) &adc_input_init_params, &adcInputTask_attributes);

  /* creation of systemTask */
  systemTaskHandle = osThreadNew(SystemTask_Init, (void*) &system_init_params, &systemTask_attributes);

  /* creation of audioTask */
  audioTaskHandle = osThreadNew(AudioTask_Init, (void*) &audio_init_params, &audioTask_attributes);

  /* creation of system_init_event */
  system_init_eventHandle = osEventFlagsNew(&system_init_event_attributes);

  /* USER CODE BEGIN RTOS_EVENTS */
  /* add events, ... */
  system_init_params.system_init_event = system_init_eventHandle;
  adc_input_init_params.system_init_event = system_init_eventHandle;
  display_init_params.system_init_event = system_init_eventHandle;
  input_init_params.system_init_event = system_init_eventHandle;
  state_init_params.system_init_event = system_init_eventHandle;
  audio_init_params.system_init_event = system_init_eventHandle;
  /* USER CODE END RTOS_EVENTS */

  /* Start scheduler */
  osKernelStart();

  /* We should never get here as control is now taken by the scheduler */

  /* Infinite loop */
  while (1) {

  }
}

void SystemClock_Config(void)
{
  RCC_OscInitTypeDef RCC_OscInitStruct = {0};
  RCC_ClkInitTypeDef RCC_ClkInitStruct = {0};

  /** Supply configuration update enable
  */
  HAL_PWREx_ConfigSupply(PWR_LDO_SUPPLY);

  /** Configure the main internal regulator output voltage
  */
  __HAL_PWR_VOLTAGESCALING_CONFIG(PWR_REGULATOR_VOLTAGE_SCALE0);

  while(!__HAL_PWR_GET_FLAG(PWR_FLAG_VOSRDY)) {}

  /** Initializes the RCC Oscillators according to the specified parameters
  * in the RCC_OscInitTypeDef structure.
  */
  RCC_OscInitStruct.OscillatorType = RCC_OSCILLATORTYPE_HSI;
  RCC_OscInitStruct.HSIState = RCC_HSI_DIV1;
  RCC_OscInitStruct.HSICalibrationValue = RCC_HSICALIBRATION_DEFAULT;
  RCC_OscInitStruct.PLL.PLLState = RCC_PLL_ON;
  RCC_OscInitStruct.PLL.PLLSource = RCC_PLLSOURCE_HSI;
  RCC_OscInitStruct.PLL.PLLM = 4;
  RCC_OscInitStruct.PLL.PLLN = 60;
  RCC_OscInitStruct.PLL.PLLP = 2;
  RCC_OscInitStruct.PLL.PLLQ = 5;
  RCC_OscInitStruct.PLL.PLLR = 42;
  RCC_OscInitStruct.PLL.PLLRGE = RCC_PLL1VCIRANGE_3;
  RCC_OscInitStruct.PLL.PLLVCOSEL = RCC_PLL1VCOWIDE;
  RCC_OscInitStruct.PLL.PLLFRACN = 0;
  if (HAL_RCC_OscConfig(&RCC_OscInitStruct) != HAL_OK)
  {
    Error_Handler();
  }

  /** Initializes the CPU, AHB and APB buses clocks
  */
  RCC_ClkInitStruct.ClockType = RCC_CLOCKTYPE_HCLK|RCC_CLOCKTYPE_SYSCLK
                              |RCC_CLOCKTYPE_PCLK1|RCC_CLOCKTYPE_PCLK2
                              |RCC_CLOCKTYPE_D3PCLK1|RCC_CLOCKTYPE_D1PCLK1;
  RCC_ClkInitStruct.SYSCLKSource = RCC_SYSCLKSOURCE_PLLCLK;
  RCC_ClkInitStruct.SYSCLKDivider = RCC_SYSCLK_DIV1;
  RCC_ClkInitStruct.AHBCLKDivider = RCC_HCLK_DIV2;
  RCC_ClkInitStruct.APB3CLKDivider = RCC_APB3_DIV2;
  RCC_ClkInitStruct.APB1CLKDivider = RCC_APB1_DIV2;
  RCC_ClkInitStruct.APB2CLKDivider = RCC_APB2_DIV2;
  RCC_ClkInitStruct.APB4CLKDivider = RCC_APB4_DIV2;

  if (HAL_RCC_ClockConfig(&RCC_ClkInitStruct, FLASH_LATENCY_4) != HAL_OK)
  {
    Error_Handler();
  }
}

void PeriphCommonClock_Config(void)
{
  RCC_PeriphCLKInitTypeDef PeriphClkInitStruct = {0};

  /** Initializes the peripherals clock
  */
  PeriphClkInitStruct.PeriphClockSelection = RCC_PERIPHCLK_SAI1;
  PeriphClkInitStruct.PLL3.PLL3M = 25;
  PeriphClkInitStruct.PLL3.PLL3N = 176;
  PeriphClkInitStruct.PLL3.PLL3P = 40;
  PeriphClkInitStruct.PLL3.PLL3Q = 2;
  PeriphClkInitStruct.PLL3.PLL3R = 2;
  PeriphClkInitStruct.PLL3.PLL3RGE = RCC_PLL3VCIRANGE_1;
  PeriphClkInitStruct.PLL3.PLL3VCOSEL = RCC_PLL3VCOWIDE;
  PeriphClkInitStruct.PLL3.PLL3FRACN = 3277;
  PeriphClkInitStruct.Sai1ClockSelection = RCC_SAI1CLKSOURCE_PLL3;
  if (HAL_RCCEx_PeriphCLKConfig(&PeriphClkInitStruct) != HAL_OK)
  {
    Error_Handler();
  }
}

static void MX_ADC1_Init(void)
{

  ADC_MultiModeTypeDef multimode = {0};
  ADC_ChannelConfTypeDef sConfig = {0};

  /** Common config
  */
  hadc1.Instance = ADC1;
  hadc1.Init.ClockPrescaler = ADC_CLOCK_ASYNC_DIV1;
  hadc1.Init.Resolution = ADC_RESOLUTION_16B;
  hadc1.Init.ScanConvMode = ADC_SCAN_ENABLE;
  hadc1.Init.EOCSelection = ADC_EOC_SINGLE_CONV;
  hadc1.Init.LowPowerAutoWait = ENABLE;
  hadc1.Init.ContinuousConvMode = DISABLE;
  hadc1.Init.NbrOfConversion = 3;
  hadc1.Init.DiscontinuousConvMode = DISABLE;
  hadc1.Init.ExternalTrigConv = ADC_SOFTWARE_START;
  hadc1.Init.ExternalTrigConvEdge = ADC_EXTERNALTRIGCONVEDGE_NONE;
  hadc1.Init.ConversionDataManagement = ADC_CONVERSIONDATA_DR;
  hadc1.Init.Overrun = ADC_OVR_DATA_PRESERVED;
  hadc1.Init.LeftBitShift = ADC_LEFTBITSHIFT_NONE;
  hadc1.Init.OversamplingMode = DISABLE;
  hadc1.Init.Oversampling.Ratio = 1;
  if (HAL_ADC_Init(&hadc1) != HAL_OK)
  {
    Error_Handler();
  }

  /** Configure the ADC multi-mode
  */
  multimode.Mode = ADC_MODE_INDEPENDENT;
  if (HAL_ADCEx_MultiModeConfigChannel(&hadc1, &multimode) != HAL_OK)
  {
    Error_Handler();
  }

  /** Configure Regular Channel
  */
  sConfig.Channel = ADC_CHANNEL_16;
  sConfig.Rank = ADC_REGULAR_RANK_1;
  sConfig.SamplingTime = ADC_SAMPLETIME_64CYCLES_5;
  sConfig.SingleDiff = ADC_SINGLE_ENDED;
  sConfig.OffsetNumber = ADC_OFFSET_NONE;
  sConfig.Offset = 0;
  sConfig.OffsetSignedSaturation = DISABLE;
  if (HAL_ADC_ConfigChannel(&hadc1, &sConfig) != HAL_OK)
  {
    Error_Handler();
  }

  /** Configure Regular Channel
  */
  sConfig.Channel = ADC_CHANNEL_17;
  sConfig.Rank = ADC_REGULAR_RANK_2;
  if (HAL_ADC_ConfigChannel(&hadc1, &sConfig) != HAL_OK)
  {
    Error_Handler();
  }

  /** Configure Regular Channel
  */
  sConfig.Channel = ADC_CHANNEL_14;
  sConfig.Rank = ADC_REGULAR_RANK_3;
  if (HAL_ADC_ConfigChannel(&hadc1, &sConfig) != HAL_OK)
  {
    Error_Handler();
  }

}

static void MX_I2C1_Init(void)
{

  hi2c1.Instance = I2C1;
  hi2c1.Init.Timing = 0x307075B1;
  hi2c1.Init.OwnAddress1 = 0;
  hi2c1.Init.AddressingMode = I2C_ADDRESSINGMODE_7BIT;
  hi2c1.Init.DualAddressMode = I2C_DUALADDRESS_DISABLE;
  hi2c1.Init.OwnAddress2 = 0;
  hi2c1.Init.OwnAddress2Masks = I2C_OA2_NOMASK;
  hi2c1.Init.GeneralCallMode = I2C_GENERALCALL_DISABLE;
  hi2c1.Init.NoStretchMode = I2C_NOSTRETCH_DISABLE;
  if (HAL_I2C_Init(&hi2c1) != HAL_OK)
  {
    Error_Handler();
  }

  /** Configure Analogue filter
  */
  if (HAL_I2CEx_ConfigAnalogFilter(&hi2c1, I2C_ANALOGFILTER_ENABLE) != HAL_OK)
  {
    Error_Handler();
  }

  /** Configure Digital filter
  */
  if (HAL_I2CEx_ConfigDigitalFilter(&hi2c1, 0) != HAL_OK)
  {
    Error_Handler();
  }

}

static void MX_SAI1_Init(void)
{

  hsai_BlockA1.Instance = SAI1_Block_A;
  hsai_BlockA1.Init.AudioMode = SAI_MODEMASTER_TX;
  hsai_BlockA1.Init.Synchro = SAI_ASYNCHRONOUS;
  hsai_BlockA1.Init.OutputDrive = SAI_OUTPUTDRIVE_DISABLE;
  hsai_BlockA1.Init.NoDivider = SAI_MCK_OVERSAMPLING_DISABLE;
  hsai_BlockA1.Init.MckOverSampling = SAI_MCK_OVERSAMPLING_DISABLE;
  hsai_BlockA1.Init.FIFOThreshold = SAI_FIFOTHRESHOLD_EMPTY;
  hsai_BlockA1.Init.AudioFrequency = SAI_AUDIO_FREQUENCY_44K;
  hsai_BlockA1.Init.SynchroExt = SAI_SYNCEXT_DISABLE;
  hsai_BlockA1.Init.MonoStereoMode = SAI_STEREOMODE;
  hsai_BlockA1.Init.CompandingMode = SAI_NOCOMPANDING;
  hsai_BlockA1.Init.TriState = SAI_OUTPUT_NOTRELEASED;
  if (HAL_SAI_InitProtocol(&hsai_BlockA1, SAI_I2S_STANDARD, SAI_PROTOCOL_DATASIZE_32BIT, 2) != HAL_OK)
  {
    Error_Handler();
  }
  hsai_BlockB1.Instance = SAI1_Block_B;
  hsai_BlockB1.Init.AudioMode = SAI_MODESLAVE_RX;
  hsai_BlockB1.Init.Synchro = SAI_SYNCHRONOUS;
  hsai_BlockB1.Init.OutputDrive = SAI_OUTPUTDRIVE_DISABLE;
  hsai_BlockB1.Init.MckOverSampling = SAI_MCK_OVERSAMPLING_DISABLE;
  hsai_BlockB1.Init.FIFOThreshold = SAI_FIFOTHRESHOLD_EMPTY;
  hsai_BlockB1.Init.SynchroExt = SAI_SYNCEXT_DISABLE;
  hsai_BlockB1.Init.MonoStereoMode = SAI_STEREOMODE;
  hsai_BlockB1.Init.CompandingMode = SAI_NOCOMPANDING;
  hsai_BlockB1.Init.TriState = SAI_OUTPUT_NOTRELEASED;
  if (HAL_SAI_InitProtocol(&hsai_BlockB1, SAI_I2S_STANDARD, SAI_PROTOCOL_DATASIZE_32BIT, 2) != HAL_OK)
  {
    Error_Handler();
  }

}

static void MX_SDMMC1_SD_Init(void)
{

  hsd1.Instance = SDMMC1;
  hsd1.Init.ClockEdge = SDMMC_CLOCK_EDGE_RISING;
  hsd1.Init.ClockPowerSave = SDMMC_CLOCK_POWER_SAVE_DISABLE;
  hsd1.Init.BusWide = SDMMC_BUS_WIDE_4B;
  hsd1.Init.HardwareFlowControl = SDMMC_HARDWARE_FLOW_CONTROL_DISABLE;
  hsd1.Init.ClockDiv = 24;
  if (HAL_SD_Init(&hsd1) != HAL_OK)
  {
    Error_Handler();
  }

}

static void MX_SPI2_Init(void)
{

  /* SPI2 parameter configuration*/
  hspi2.Instance = SPI2;
  hspi2.Init.Mode = SPI_MODE_MASTER;
  hspi2.Init.Direction = SPI_DIRECTION_2LINES_TXONLY;
  hspi2.Init.DataSize = SPI_DATASIZE_8BIT;
  hspi2.Init.CLKPolarity = SPI_POLARITY_LOW;
  hspi2.Init.CLKPhase = SPI_PHASE_1EDGE;
  hspi2.Init.NSS = SPI_NSS_SOFT;
  hspi2.Init.BaudRatePrescaler = SPI_BAUDRATEPRESCALER_16;
  hspi2.Init.FirstBit = SPI_FIRSTBIT_MSB;
  hspi2.Init.TIMode = SPI_TIMODE_DISABLE;
  hspi2.Init.CRCCalculation = SPI_CRCCALCULATION_DISABLE;
  hspi2.Init.CRCPolynomial = 0x0;
  hspi2.Init.NSSPMode = SPI_NSS_PULSE_ENABLE;
  hspi2.Init.NSSPolarity = SPI_NSS_POLARITY_LOW;
  hspi2.Init.FifoThreshold = SPI_FIFO_THRESHOLD_01DATA;
  hspi2.Init.TxCRCInitializationPattern = SPI_CRC_INITIALIZATION_ALL_ZERO_PATTERN;
  hspi2.Init.RxCRCInitializationPattern = SPI_CRC_INITIALIZATION_ALL_ZERO_PATTERN;
  hspi2.Init.MasterSSIdleness = SPI_MASTER_SS_IDLENESS_00CYCLE;
  hspi2.Init.MasterInterDataIdleness = SPI_MASTER_INTERDATA_IDLENESS_00CYCLE;
  hspi2.Init.MasterReceiverAutoSusp = SPI_MASTER_RX_AUTOSUSP_DISABLE;
  hspi2.Init.MasterKeepIOState = SPI_MASTER_KEEP_IO_STATE_DISABLE;
  hspi2.Init.IOSwap = SPI_IO_SWAP_DISABLE;
  if (HAL_SPI_Init(&hspi2) != HAL_OK)
  {
    Error_Handler();
  }

}

static void MX_TIM2_Init(void)
{

  TIM_Encoder_InitTypeDef sConfig = {0};
  TIM_MasterConfigTypeDef sMasterConfig = {0};

  htim2.Instance = TIM2;
  htim2.Init.Prescaler = 0;
  htim2.Init.CounterMode = TIM_COUNTERMODE_UP;
  htim2.Init.Period = 65535;
  htim2.Init.ClockDivision = TIM_CLOCKDIVISION_DIV1;
  htim2.Init.AutoReloadPreload = TIM_AUTORELOAD_PRELOAD_DISABLE;
  sConfig.EncoderMode = TIM_ENCODERMODE_TI1;
  sConfig.IC1Polarity = TIM_ICPOLARITY_RISING;
  sConfig.IC1Selection = TIM_ICSELECTION_DIRECTTI;
  sConfig.IC1Prescaler = TIM_ICPSC_DIV1;
  sConfig.IC1Filter = 0;
  sConfig.IC2Polarity = TIM_ICPOLARITY_RISING;
  sConfig.IC2Selection = TIM_ICSELECTION_DIRECTTI;
  sConfig.IC2Prescaler = TIM_ICPSC_DIV1;
  sConfig.IC2Filter = 0;
  if (HAL_TIM_Encoder_Init(&htim2, &sConfig) != HAL_OK)
  {
    Error_Handler();
  }
  sMasterConfig.MasterOutputTrigger = TIM_TRGO_RESET;
  sMasterConfig.MasterSlaveMode = TIM_MASTERSLAVEMODE_DISABLE;
  if (HAL_TIMEx_MasterConfigSynchronization(&htim2, &sMasterConfig) != HAL_OK)
  {
    Error_Handler();
  }

}

static void MX_TIM3_Init(void)
{

  TIM_Encoder_InitTypeDef sConfig = {0};
  TIM_MasterConfigTypeDef sMasterConfig = {0};

  htim3.Instance = TIM3;
  htim3.Init.Prescaler = 0;
  htim3.Init.CounterMode = TIM_COUNTERMODE_UP;
  htim3.Init.Period = 65535;
  htim3.Init.ClockDivision = TIM_CLOCKDIVISION_DIV1;
  htim3.Init.AutoReloadPreload = TIM_AUTORELOAD_PRELOAD_DISABLE;
  sConfig.EncoderMode = TIM_ENCODERMODE_TI1;
  sConfig.IC1Polarity = TIM_ICPOLARITY_RISING;
  sConfig.IC1Selection = TIM_ICSELECTION_DIRECTTI;
  sConfig.IC1Prescaler = TIM_ICPSC_DIV1;
  sConfig.IC1Filter = 0;
  sConfig.IC2Polarity = TIM_ICPOLARITY_RISING;
  sConfig.IC2Selection = TIM_ICSELECTION_DIRECTTI;
  sConfig.IC2Prescaler = TIM_ICPSC_DIV1;
  sConfig.IC2Filter = 0;
  if (HAL_TIM_Encoder_Init(&htim3, &sConfig) != HAL_OK)
  {
    Error_Handler();
  }
  sMasterConfig.MasterOutputTrigger = TIM_TRGO_RESET;
  sMasterConfig.MasterSlaveMode = TIM_MASTERSLAVEMODE_DISABLE;
  if (HAL_TIMEx_MasterConfigSynchronization(&htim3, &sMasterConfig) != HAL_OK)
  {
    Error_Handler();
  }

}

static void MX_TIM5_Init(void)
{

  TIM_Encoder_InitTypeDef sConfig = {0};
  TIM_MasterConfigTypeDef sMasterConfig = {0};

  htim5.Instance = TIM5;
  htim5.Init.Prescaler = 0;
  htim5.Init.CounterMode = TIM_COUNTERMODE_UP;
  htim5.Init.Period = 65535;
  htim5.Init.ClockDivision = TIM_CLOCKDIVISION_DIV1;
  htim5.Init.AutoReloadPreload = TIM_AUTORELOAD_PRELOAD_DISABLE;
  sConfig.EncoderMode = TIM_ENCODERMODE_TI1;
  sConfig.IC1Polarity = TIM_ICPOLARITY_RISING;
  sConfig.IC1Selection = TIM_ICSELECTION_DIRECTTI;
  sConfig.IC1Prescaler = TIM_ICPSC_DIV1;
  sConfig.IC1Filter = 0;
  sConfig.IC2Polarity = TIM_ICPOLARITY_RISING;
  sConfig.IC2Selection = TIM_ICSELECTION_DIRECTTI;
  sConfig.IC2Prescaler = TIM_ICPSC_DIV1;
  sConfig.IC2Filter = 0;
  if (HAL_TIM_Encoder_Init(&htim5, &sConfig) != HAL_OK)
  {
    Error_Handler();
  }
  sMasterConfig.MasterOutputTrigger = TIM_TRGO_RESET;
  sMasterConfig.MasterSlaveMode = TIM_MASTERSLAVEMODE_DISABLE;
  if (HAL_TIMEx_MasterConfigSynchronization(&htim5, &sMasterConfig) != HAL_OK)
  {
    Error_Handler();
  }

}

static void MX_TIM8_Init(void)
{

  TIM_Encoder_InitTypeDef sConfig = {0};
  TIM_MasterConfigTypeDef sMasterConfig = {0};

  htim8.Instance = TIM8;
  htim8.Init.Prescaler = 0;
  htim8.Init.CounterMode = TIM_COUNTERMODE_UP;
  htim8.Init.Period = 65535;
  htim8.Init.ClockDivision = TIM_CLOCKDIVISION_DIV1;
  htim8.Init.RepetitionCounter = 0;
  htim8.Init.AutoReloadPreload = TIM_AUTORELOAD_PRELOAD_DISABLE;
  sConfig.EncoderMode = TIM_ENCODERMODE_TI1;
  sConfig.IC1Polarity = TIM_ICPOLARITY_RISING;
  sConfig.IC1Selection = TIM_ICSELECTION_DIRECTTI;
  sConfig.IC1Prescaler = TIM_ICPSC_DIV1;
  sConfig.IC1Filter = 0;
  sConfig.IC2Polarity = TIM_ICPOLARITY_RISING;
  sConfig.IC2Selection = TIM_ICSELECTION_DIRECTTI;
  sConfig.IC2Prescaler = TIM_ICPSC_DIV1;
  sConfig.IC2Filter = 0;
  if (HAL_TIM_Encoder_Init(&htim8, &sConfig) != HAL_OK)
  {
    Error_Handler();
  }
  sMasterConfig.MasterOutputTrigger = TIM_TRGO_RESET;
  sMasterConfig.MasterOutputTrigger2 = TIM_TRGO2_RESET;
  sMasterConfig.MasterSlaveMode = TIM_MASTERSLAVEMODE_DISABLE;
  if (HAL_TIMEx_MasterConfigSynchronization(&htim8, &sMasterConfig) != HAL_OK)
  {
    Error_Handler();
  }

}

static void MX_DMA_Init(void)
{

  /* DMA controller clock enable */
  __HAL_RCC_DMA1_CLK_ENABLE();

  /* DMA interrupt init */
  /* DMA1_Stream0_IRQn interrupt configuration */
  HAL_NVIC_SetPriority(DMA1_Stream0_IRQn, 5, 0);
  HAL_NVIC_EnableIRQ(DMA1_Stream0_IRQn);
  /* DMA1_Stream1_IRQn interrupt configuration */
  HAL_NVIC_SetPriority(DMA1_Stream1_IRQn, 5, 0);
  HAL_NVIC_EnableIRQ(DMA1_Stream1_IRQn);
  /* DMA1_Stream2_IRQn interrupt configuration */
  HAL_NVIC_SetPriority(DMA1_Stream2_IRQn, 5, 0);
  HAL_NVIC_EnableIRQ(DMA1_Stream2_IRQn);

}

/**
  * Enable MDMA controller clock
  * Configure MDMA for global transfers
  *   hmdma_mdma_channel0_sw_0
  */
static void MX_MDMA_Init(void)
{

  /* MDMA controller clock enable */
  __HAL_RCC_MDMA_CLK_ENABLE();
  /* Local variables */

  /* Configure MDMA channel MDMA_Channel0 */
  /* Configure MDMA request hmdma_mdma_channel0_sw_0 on MDMA_Channel0 */
  hmdma_mdma_channel0_sw_0.Instance = MDMA_Channel0;
  hmdma_mdma_channel0_sw_0.Init.Request = MDMA_REQUEST_SW;
  hmdma_mdma_channel0_sw_0.Init.TransferTriggerMode = MDMA_BLOCK_TRANSFER;
  hmdma_mdma_channel0_sw_0.Init.Priority = MDMA_PRIORITY_MEDIUM;
  hmdma_mdma_channel0_sw_0.Init.Endianness = MDMA_LITTLE_ENDIANNESS_PRESERVE;
  hmdma_mdma_channel0_sw_0.Init.SourceInc = MDMA_SRC_INC_WORD;
  hmdma_mdma_channel0_sw_0.Init.DestinationInc = MDMA_DEST_INC_WORD;
  hmdma_mdma_channel0_sw_0.Init.SourceDataSize = MDMA_SRC_DATASIZE_WORD;
  hmdma_mdma_channel0_sw_0.Init.DestDataSize = MDMA_DEST_DATASIZE_WORD;
  hmdma_mdma_channel0_sw_0.Init.DataAlignment = MDMA_DATAALIGN_PACKENABLE;
  hmdma_mdma_channel0_sw_0.Init.BufferTransferLength = 128;
  hmdma_mdma_channel0_sw_0.Init.SourceBurst = MDMA_SOURCE_BURST_SINGLE;
  hmdma_mdma_channel0_sw_0.Init.DestBurst = MDMA_DEST_BURST_SINGLE;
  hmdma_mdma_channel0_sw_0.Init.SourceBlockAddressOffset = 0;
  hmdma_mdma_channel0_sw_0.Init.DestBlockAddressOffset = 0;
  if (HAL_MDMA_Init(&hmdma_mdma_channel0_sw_0) != HAL_OK)
  {
    Error_Handler();
  }

  /* MDMA interrupt initialization */
  /* MDMA_IRQn interrupt configuration */
  HAL_NVIC_SetPriority(MDMA_IRQn, 5, 0);
  HAL_NVIC_EnableIRQ(MDMA_IRQn);

}

/* FMC initialization function */
static void MX_FMC_Init(void)
{

  FMC_SDRAM_TimingTypeDef SdramTiming = {0};

  /** Perform the SDRAM1 memory initialization sequence
  */
  hsdram1.Instance = FMC_SDRAM_DEVICE;
  /* hsdram1.Init */
  hsdram1.Init.SDBank = FMC_SDRAM_BANK1;
  hsdram1.Init.ColumnBitsNumber = FMC_SDRAM_COLUMN_BITS_NUM_9;
  hsdram1.Init.RowBitsNumber = FMC_SDRAM_ROW_BITS_NUM_13;
  hsdram1.Init.MemoryDataWidth = FMC_SDRAM_MEM_BUS_WIDTH_16;
  hsdram1.Init.InternalBankNumber = FMC_SDRAM_INTERN_BANKS_NUM_4;
  hsdram1.Init.CASLatency = FMC_SDRAM_CAS_LATENCY_2;
  hsdram1.Init.WriteProtection = FMC_SDRAM_WRITE_PROTECTION_DISABLE;
  hsdram1.Init.SDClockPeriod = FMC_SDRAM_CLOCK_PERIOD_3;
  hsdram1.Init.ReadBurst = FMC_SDRAM_RBURST_ENABLE;
  hsdram1.Init.ReadPipeDelay = FMC_SDRAM_RPIPE_DELAY_0;
  /* SdramTiming */
  SdramTiming.LoadToActiveDelay = 16;
  SdramTiming.ExitSelfRefreshDelay = 16;
  SdramTiming.SelfRefreshTime = 16;
  SdramTiming.RowCycleDelay = 16;
  SdramTiming.WriteRecoveryTime = 16;
  SdramTiming.RPDelay = 16;
  SdramTiming.RCDDelay = 16;

  if (HAL_SDRAM_Init(&hsdram1, &SdramTiming) != HAL_OK)
  {
    Error_Handler( );
  }

  /* USER CODE BEGIN FMC_Init 2 */
  hsdram1.hmdma = &hmdma_mdma_channel0_sw_0;
  /* USER CODE END FMC_Init 2 */
}

static void MX_GPIO_Init(void)
{
  GPIO_InitTypeDef GPIO_InitStruct = {0};

  /* GPIO Ports Clock Enable */
  __HAL_RCC_GPIOE_CLK_ENABLE();
  __HAL_RCC_GPIOF_CLK_ENABLE();
  __HAL_RCC_GPIOC_CLK_ENABLE();
  __HAL_RCC_GPIOA_CLK_ENABLE();
  __HAL_RCC_GPIOH_CLK_ENABLE();
  __HAL_RCC_GPIOB_CLK_ENABLE();
  __HAL_RCC_GPIOG_CLK_ENABLE();
  __HAL_RCC_GPIOD_CLK_ENABLE();

  /*Configure GPIO pin Output Level */
  HAL_GPIO_WritePin(GPIOD, GMG12864_CS_Pin|GMG12864_RST_Pin|GMG12864_DC_Pin, GPIO_PIN_RESET);

  /*Configure GPIO pins : MCP23017_100_INTA_Pin MCP23017_101_INTA_Pin */
  GPIO_InitStruct.Pin = MCP23017_100_INTA_Pin|MCP23017_101_INTA_Pin;
  GPIO_InitStruct.Mode = GPIO_MODE_IT_RISING;
  GPIO_InitStruct.Pull = GPIO_NOPULL;
  HAL_GPIO_Init(GPIOB, &GPIO_InitStruct);

  /*Configure GPIO pins : GMG12864_CS_Pin GMG12864_RST_Pin GMG12864_DC_Pin */
  GPIO_InitStruct.Pin = GMG12864_CS_Pin|GMG12864_RST_Pin|GMG12864_DC_Pin;
  GPIO_InitStruct.Mode = GPIO_MODE_OUTPUT_PP;
  GPIO_InitStruct.Pull = GPIO_NOPULL;
  GPIO_InitStruct.Speed = GPIO_SPEED_FREQ_LOW;
  HAL_GPIO_Init(GPIOD, &GPIO_InitStruct);

  /*Configure GPIO pin : SDMMC_Detect_Pin */
  GPIO_InitStruct.Pin = SDMMC_Detect_Pin;
  GPIO_InitStruct.Mode = GPIO_MODE_INPUT;
  GPIO_InitStruct.Pull = GPIO_PULLUP;
  HAL_GPIO_Init(SDMMC_Detect_GPIO_Port, &GPIO_InitStruct);

  /* EXTI interrupt init*/
  HAL_NVIC_SetPriority(MCP23017_100_INTA_EXTI_IRQn, 5, 0);
  HAL_NVIC_EnableIRQ(MCP23017_100_INTA_EXTI_IRQn);

  HAL_NVIC_SetPriority(MCP23017_101_INTA_EXTI_IRQn, 5, 0);
  HAL_NVIC_EnableIRQ(MCP23017_101_INTA_EXTI_IRQn);

}

void StartDefaultTask(void *argument)
{
  for(;;)
  {
    osDelay(1);
  }
}

 /* MPU Configuration */

void MPU_Config(void)
{
  MPU_Region_InitTypeDef MPU_InitStruct = {0};

  /* Disables the MPU */
  HAL_MPU_Disable();

  /** Initializes and configures the Region and the memory to be protected
  */
  MPU_InitStruct.Enable = MPU_REGION_ENABLE;
  MPU_InitStruct.Number = MPU_REGION_NUMBER0;
  MPU_InitStruct.BaseAddress = 0x0;
  MPU_InitStruct.Size = MPU_REGION_SIZE_4GB;
  MPU_InitStruct.SubRegionDisable = 0x87;
  MPU_InitStruct.TypeExtField = MPU_TEX_LEVEL0;
  MPU_InitStruct.AccessPermission = MPU_REGION_NO_ACCESS;
  MPU_InitStruct.DisableExec = MPU_INSTRUCTION_ACCESS_DISABLE;
  MPU_InitStruct.IsShareable = MPU_ACCESS_SHAREABLE;
  MPU_InitStruct.IsCacheable = MPU_ACCESS_NOT_CACHEABLE;
  MPU_InitStruct.IsBufferable = MPU_ACCESS_NOT_BUFFERABLE;

  HAL_MPU_ConfigRegion(&MPU_InitStruct);

  /** Initializes and configures the Region and the memory to be protected
  */
  MPU_InitStruct.Number = MPU_REGION_NUMBER1;
  MPU_InitStruct.BaseAddress = 0xC0000000;
  MPU_InitStruct.Size = MPU_REGION_SIZE_32MB;
  MPU_InitStruct.SubRegionDisable = 0x0;
  MPU_InitStruct.AccessPermission = MPU_REGION_FULL_ACCESS;
  MPU_InitStruct.DisableExec = MPU_INSTRUCTION_ACCESS_ENABLE;
  MPU_InitStruct.IsCacheable = MPU_ACCESS_CACHEABLE;
  MPU_InitStruct.IsBufferable = MPU_ACCESS_BUFFERABLE;

  HAL_MPU_ConfigRegion(&MPU_InitStruct);
  /* Enables the MPU */
  HAL_MPU_Enable(MPU_PRIVILEGED_DEFAULT);

}

void HAL_TIM_PeriodElapsedCallback(TIM_HandleTypeDef *htim)
{
  if (htim->Instance == TIM7)
  {
    HAL_IncTick();
  }
}

void Error_Handler(void)
{
  /* USER CODE BEGIN Error_Handler_Debug */
  /* User can add his own implementation to report the HAL error return state */
  __disable_irq();
  DebugFault_CaptureSoftwareError(DEBUG_FAULT_REASON_ERROR_HANDLER);
  while (1) {
  }
  /* USER CODE END Error_Handler_Debug */
}
#ifdef USE_FULL_ASSERT
/**
  * @brief  Reports the name of the source file and the source line number
  *         where the assert_param error has occurred.
  * @param  file: pointer to the source file name
  * @param  line: assert_param error line source number
  * @retval None
  */
void assert_failed(uint8_t *file, uint32_t line)
{
  /* USER CODE BEGIN 6 */
  /* User can add his own implementation to report the file name and line
     number, ex: printf("Wrong parameters value: file %s on line %d\r\n", file,
     line) */
  /* USER CODE END 6 */
}
#endif /* USE_FULL_ASSERT */
